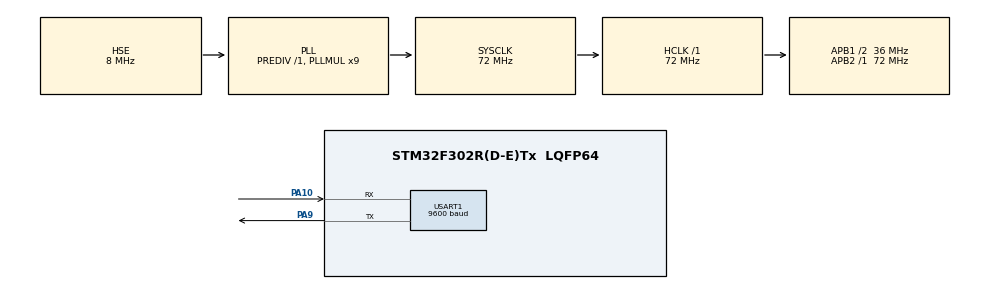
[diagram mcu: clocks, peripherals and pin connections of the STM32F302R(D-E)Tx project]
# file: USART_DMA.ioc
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Dma.Request0=USART1_RX
Dma.USART1_RX.0.Direction=DMA_PERIPH_TO_MEMORY
Dma.USART1_RX.0.Instance=DMA1_Channel5
Dma.USART1_RX.0.MemDataAlignment=DMA_MDATAALIGN_BYTE
Dma.USART1_RX.0.MemInc=DMA_MINC_ENABLE
Dma.USART1_RX.0.Mode=DMA_CIRCULAR
Dma.USART1_RX.0.PeriphDataAlignment=DMA_PDATAALIGN_BYTE
Dma.USART1_RX.0.PeriphInc=DMA_PINC_DISABLE
Dma.USART1_RX.0.Priority=DMA_PRIORITY_LOW
Mcu.Family=STM32F3
Mcu.Name=STM32F302R(D-E)Tx
Mcu.Package=LQFP64
NVIC.DMA1_Channel5_IRQn=true\:0\:0\:false\:false\:true\:false\:true
NVIC.PriorityGroup=NVIC_PRIORITYGROUP_4
PA10.Mode=Asynchronous
PA10.Signal=USART1_RX
PA9.Mode=Asynchronous
PA9.Signal=USART1_TX
PF0-OSC_IN.Mode=HSE-External-Oscillator
PF0-OSC_IN.Signal=RCC_OSC_IN
PF1-OSC_OUT.Mode=HSE-External-Oscillator
PF1-OSC_OUT.Signal=RCC_OSC_OUT
ProjectManager.HeapSize=0x200
ProjectManager.StackSize=0x400
ProjectManager.TargetToolchain=MDK-ARM V5.27
RCC.AHBFreq_Value=72000000
RCC.APB1CLKDivider=RCC_HCLK_DIV2
RCC.APB1Freq_Value=36000000
RCC.APB1TimFreq_Value=72000000
RCC.APB2Freq_Value=72000000
RCC.APB2TimFreq_Value=72000000
RCC.CortexFreq_Value=72000000
RCC.HCLKFreq_Value=72000000
RCC.HSE_VALUE=8000000
RCC.HSI_VALUE=8000000
RCC.LSE_VALUE=32768
RCC.PLLMUL=RCC_PLL_MUL9
RCC.PLLSourceVirtual=RCC_PLLSOURCE_HSE
RCC.SYSCLKFreq_VALUE=72000000
RCC.SYSCLKSourceVirtual=RCC_SYSCLKSOURCE_PLLCLK
RCC.USBFreq_Value=72000000
USART1.BaudRate=9600
USART1.VirtualMode-Asynchronous=VM_ASYNC
board=custom

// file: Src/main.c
/* USER CODE BEGIN Header */
/**
  ******************************************************************************
  * @file           : main.c
  * @brief          : Main program body
  ******************************************************************************
  * @attention
  *
  * <h2><center>&copy; Copyright (c) 2020 STMicroelectronics.
  * All rights reserved.</center></h2>
  *
  * This software component is licensed by ST under BSD 3-Clause license,
  * the "License"; You may not use this file except in compliance with the
  * License. You may obtain a copy of the License at:
  *                        opensource.org/licenses/BSD-3-Clause
  *
  ******************************************************************************
  */
/* USER CODE END Header */

#include "main.h"

UART_HandleTypeDef huart1;
DMA_HandleTypeDef hdma_usart1_rx;

/* USER CODE BEGIN PV */
uint8_t rx_buffer;
uint8_t Tx_Data = 0;
/* USER CODE END PV */

void SystemClock_Config(void);
static void MX_GPIO_Init(void);
static void MX_DMA_Init(void);
static void MX_USART1_UART_Init(void);

int main(void)
{

  /* MCU Configuration--------------------------------------------------------*/

  /* Reset of all peripherals, Initializes the Flash interface and the Systick. */
  HAL_Init();

  /* Configure the system clock */
  SystemClock_Config();

  /* Initialize all configured peripherals */
  MX_GPIO_Init();
  MX_DMA_Init();
  MX_USART1_UART_Init();
  /* USER CODE BEGIN 2 */
	HAL_UART_Receive_DMA(&huart1,&rx_buffer,1);
  /* USER CODE END 2 */

  /* Infinite loop */
  /* USER CODE BEGIN WHILE */
  while (1)
  {
//		if(rx_buffer != 0)
//		{
//			HAL_UART_Transmit(&huart1,&rx_buffer,1,1000);
//			rx_buffer = 0;
//		}
		HAL_UART_Transmit(&huart1,&Tx_Data,1,1000);
		Tx_Data++;
		HAL_Delay(100);
    /* USER CODE END WHILE */

  }
}

void SystemClock_Config(void)
{
  RCC_OscInitTypeDef RCC_OscInitStruct = {0};
  RCC_ClkInitTypeDef RCC_ClkInitStruct = {0};
  RCC_PeriphCLKInitTypeDef PeriphClkInit = {0};

  /** Initializes the CPU, AHB and APB busses clocks
  */
  RCC_OscInitStruct.OscillatorType = RCC_OSCILLATORTYPE_HSE;
  RCC_OscInitStruct.HSEState = RCC_HSE_ON;
  RCC_OscInitStruct.HSIState = RCC_HSI_ON;
  RCC_OscInitStruct.PLL.PLLState = RCC_PLL_ON;
  RCC_OscInitStruct.PLL.PLLSource = RCC_PLLSOURCE_HSE;
  RCC_OscInitStruct.PLL.PLLMUL = RCC_PLL_MUL9;
  RCC_OscInitStruct.PLL.PREDIV = RCC_PREDIV_DIV1;
  if (HAL_RCC_OscConfig(&RCC_OscInitStruct) != HAL_OK)
  {
    Error_Handler();
  }
  /** Initializes the CPU, AHB and APB busses clocks
  */
  RCC_ClkInitStruct.ClockType = RCC_CLOCKTYPE_HCLK|RCC_CLOCKTYPE_SYSCLK
                              |RCC_CLOCKTYPE_PCLK1|RCC_CLOCKTYPE_PCLK2;
  RCC_ClkInitStruct.SYSCLKSource = RCC_SYSCLKSOURCE_PLLCLK;
  RCC_ClkInitStruct.AHBCLKDivider = RCC_SYSCLK_DIV1;
  RCC_ClkInitStruct.APB1CLKDivider = RCC_HCLK_DIV2;
  RCC_ClkInitStruct.APB2CLKDivider = RCC_HCLK_DIV1;

  if (HAL_RCC_ClockConfig(&RCC_ClkInitStruct, FLASH_LATENCY_2) != HAL_OK)
  {
    Error_Handler();
  }
  PeriphClkInit.PeriphClockSelection = RCC_PERIPHCLK_USART1;
  PeriphClkInit.Usart1ClockSelection = RCC_USART1CLKSOURCE_PCLK2;
  if (HAL_RCCEx_PeriphCLKConfig(&PeriphClkInit) != HAL_OK)
  {
    Error_Handler();
  }
}

static void MX_USART1_UART_Init(void)
{

  huart1.Instance = USART1;
  huart1.Init.BaudRate = 9600;
  huart1.Init.WordLength = UART_WORDLENGTH_8B;
  huart1.Init.StopBits = UART_STOPBITS_1;
  huart1.Init.Parity = UART_PARITY_NONE;
  huart1.Init.Mode = UART_MODE_TX_RX;
  huart1.Init.HwFlowCtl = UART_HWCONTROL_NONE;
  huart1.Init.OverSampling = UART_OVERSAMPLING_16;
  huart1.Init.OneBitSampling = UART_ONE_BIT_SAMPLE_DISABLE;
  huart1.AdvancedInit.AdvFeatureInit = UART_ADVFEATURE_NO_INIT;
  if (HAL_UART_Init(&huart1) != HAL_OK)
  {
    Error_Handler();
  }

}

static void MX_DMA_Init(void)
{

  /* DMA controller clock enable */
  __HAL_RCC_DMA1_CLK_ENABLE();

  /* DMA interrupt init */
  /* DMA1_Channel5_IRQn interrupt configuration */
  HAL_NVIC_SetPriority(DMA1_Channel5_IRQn, 0, 0);
  HAL_NVIC_EnableIRQ(DMA1_Channel5_IRQn);

}

static void MX_GPIO_Init(void)
{

  /* GPIO Ports Clock Enable */
  __HAL_RCC_GPIOF_CLK_ENABLE();
  __HAL_RCC_GPIOA_CLK_ENABLE();

}

void Error_Handler(void)
{
}

/************************ (C) COPYRIGHT STMicroelectronics *****END OF FILE****/
